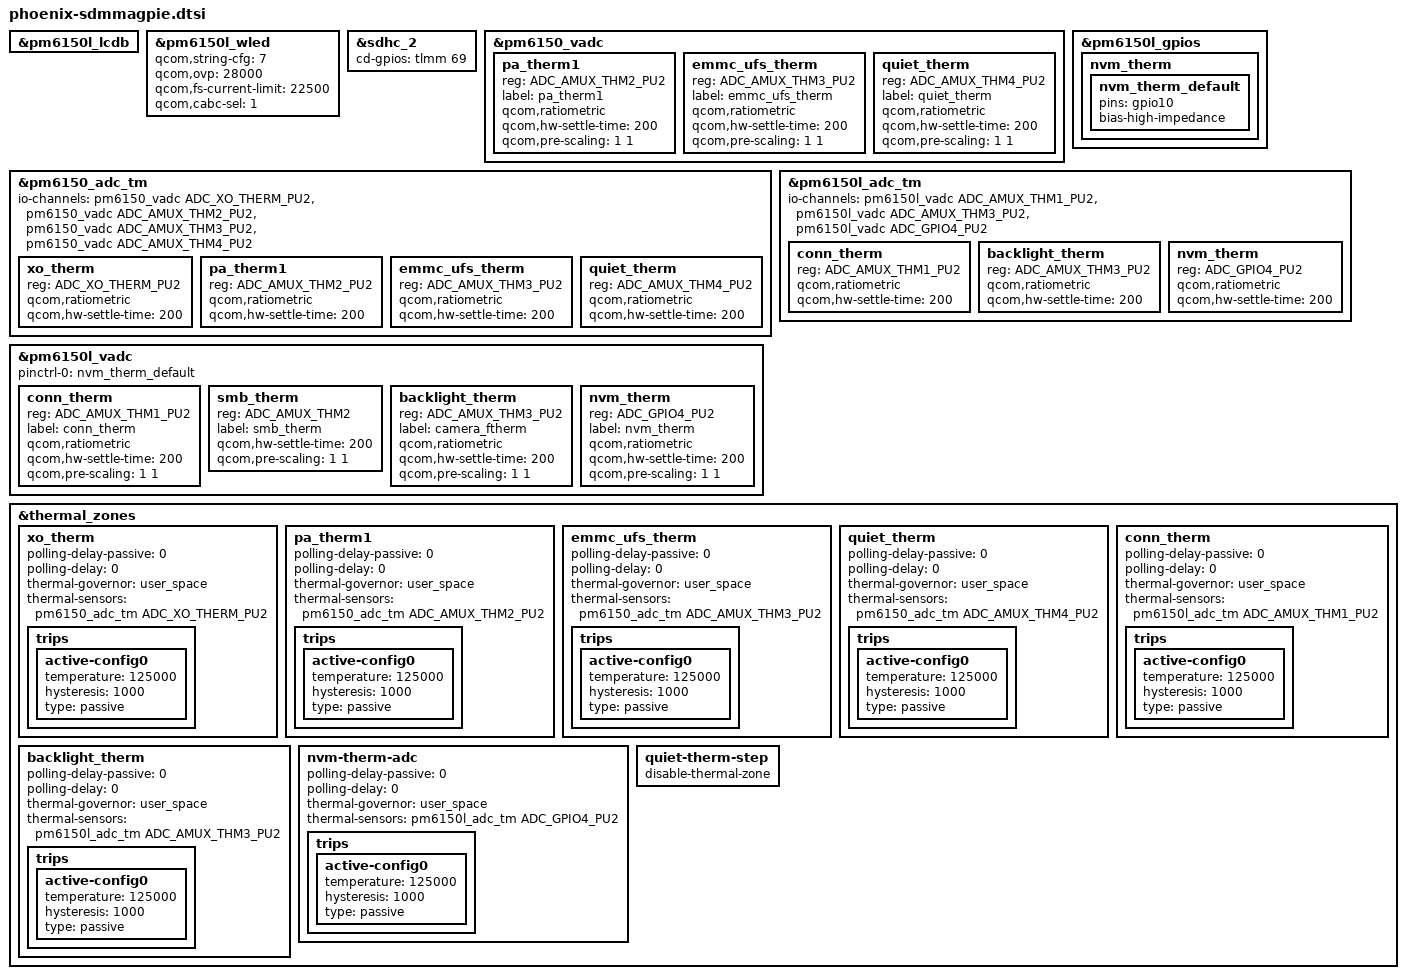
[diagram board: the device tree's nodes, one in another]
/* Copyright (c) 2018-2019, The Linux Foundation. All rights reserved.
 * Copyright (C) 2020 The LineageOS Project
 *
 * This program is free software; you can redistribute it and/or modify
 * it under the terms of the GNU General Public License version 2 and
 * only version 2 as published by the Free Software Foundation.
 *
 * This program is distributed in the hope that it will be useful,
 * but WITHOUT ANY WARRANTY; without even the implied warranty of
 * MERCHANTABILITY or FITNESS FOR A PARTICULAR PURPOSE.  See the
 * GNU General Public License for more details.
 */

#include "../common/xiaomi-sdmmagpie-common.dtsi"

#include "phoenix-audio-overlay.dtsi"
#include "phoenix-nfc-overlay.dtsi"
#include "phoenix-sdmmagpie-battery.dtsi"
#include "phoenix-sdmmagpie-camera-sensor.dtsi"
#include "phoenix-sdmmagpie-display.dtsi"
#include "phoenix-sdmmagpie-fingerprint.dtsi"
#include "phoenix-sdmmagpie-leds.dtsi"
#include "phoenix-sdmmagpie-pinctrl.dtsi"
#include "phoenix-sdmmagpie-touchscreen.dtsi"
#include "phoenix-sdmmagpie-usb.dtsi"

&pm6150l_lcdb {
    status = "okay";
};

&pm6150l_wled {
    status = "okay";
    qcom,string-cfg = <7>;
    qcom,ovp = <28000>;
    qcom,fs-current-limit = <22500>;
    qcom,cabc-sel = <1>;
};

&sdhc_2 {
    cd-gpios = <&tlmm 69 GPIO_ACTIVE_HIGH>;
    status = "ok";
};

&pm6150_vadc {
    pa_therm1 {
        reg = <ADC_AMUX_THM2_PU2>;
        label = "pa_therm1";
        qcom,ratiometric;
        qcom,hw-settle-time = <200>;
        qcom,pre-scaling = <1 1>;
    };

    emmc_ufs_therm {
        reg = <ADC_AMUX_THM3_PU2>;
        label = "emmc_ufs_therm";
        qcom,ratiometric;
        qcom,hw-settle-time = <200>;
        qcom,pre-scaling = <1 1>;
    };

    quiet_therm {
        reg = <ADC_AMUX_THM4_PU2>;
        label = "quiet_therm";
        qcom,ratiometric;
        qcom,hw-settle-time = <200>;
        qcom,pre-scaling = <1 1>;
    };
};

&pm6150_adc_tm {
    io-channels = <&pm6150_vadc ADC_XO_THERM_PU2>,
            <&pm6150_vadc ADC_AMUX_THM2_PU2>,
            <&pm6150_vadc ADC_AMUX_THM3_PU2>,
            <&pm6150_vadc ADC_AMUX_THM4_PU2>;

    /* Channel nodes */
    xo_therm {
        reg = <ADC_XO_THERM_PU2>;
        qcom,ratiometric;
        qcom,hw-settle-time = <200>;
    };

    pa_therm1 {
        reg = <ADC_AMUX_THM2_PU2>;
        qcom,ratiometric;
        qcom,hw-settle-time = <200>;
    };

    emmc_ufs_therm {
        reg = <ADC_AMUX_THM3_PU2>;
        qcom,ratiometric;
        qcom,hw-settle-time = <200>;
    };

    quiet_therm {
        reg = <ADC_AMUX_THM4_PU2>;
        qcom,ratiometric;
        qcom,hw-settle-time = <200>;
    };
};

&pm6150l_vadc {
    pinctrl-names = "default";
    pinctrl-0 = <&nvm_therm_default>;

    conn_therm {
        reg = <ADC_AMUX_THM1_PU2>;
        label = "conn_therm";
        qcom,ratiometric;
        qcom,hw-settle-time = <200>;
        qcom,pre-scaling = <1 1>;
    };

    smb_therm {
        reg = <ADC_AMUX_THM2>;
        label = "smb_therm";
        qcom,hw-settle-time = <200>;
        qcom,pre-scaling = <1 1>;
    };

    backlight_therm {
        reg = <ADC_AMUX_THM3_PU2>;
        label = "camera_ftherm";
        qcom,ratiometric;
        qcom,hw-settle-time = <200>;
        qcom,pre-scaling = <1 1>;
    };

    nvm_therm {
        reg = <ADC_GPIO4_PU2>;
        label = "nvm_therm";
        qcom,ratiometric;
        qcom,hw-settle-time = <200>;
        qcom,pre-scaling = <1 1>;
    };
};

&pm6150l_gpios {
    nvm_therm {
        nvm_therm_default: nvm_therm_default {
            pins = "gpio10";
            bias-high-impedance;
        };
    };
};

&pm6150l_adc_tm {
    io-channels = <&pm6150l_vadc ADC_AMUX_THM1_PU2>,
            <&pm6150l_vadc ADC_AMUX_THM3_PU2>,
            <&pm6150l_vadc ADC_GPIO4_PU2>;

    /* Channel nodes */
    conn_therm {
        reg = <ADC_AMUX_THM1_PU2>;
        qcom,ratiometric;
        qcom,hw-settle-time = <200>;
    };

    backlight_therm {
        reg = <ADC_AMUX_THM3_PU2>;
        qcom,ratiometric;
        qcom,hw-settle-time = <200>;
    };

    nvm_therm {
        reg = <ADC_GPIO4_PU2>;
        qcom,ratiometric;
        qcom,hw-settle-time = <200>;
    };
};

&thermal_zones {
    xo_therm {
        polling-delay-passive = <0>;
        polling-delay = <0>;
        thermal-governor = "user_space";
        thermal-sensors = <&pm6150_adc_tm ADC_XO_THERM_PU2>;
        trips {
            active-config0 {
                temperature = <125000>;
                hysteresis = <1000>;
                type = "passive";
            };
        };
    };

    pa_therm1 {
        polling-delay-passive = <0>;
        polling-delay = <0>;
        thermal-governor = "user_space";
        thermal-sensors = <&pm6150_adc_tm ADC_AMUX_THM2_PU2>;
        trips {
            active-config0 {
                temperature = <125000>;
                hysteresis = <1000>;
                type = "passive";
            };
        };
    };

    emmc_ufs_therm {
        polling-delay-passive = <0>;
        polling-delay = <0>;
        thermal-governor = "user_space";
        thermal-sensors = <&pm6150_adc_tm ADC_AMUX_THM3_PU2>;
        trips {
            active-config0 {
                temperature = <125000>;
                hysteresis = <1000>;
                type = "passive";
            };
        };
    };

    quiet_therm {
        polling-delay-passive = <0>;
        polling-delay = <0>;
        thermal-governor = "user_space";
        thermal-sensors = <&pm6150_adc_tm ADC_AMUX_THM4_PU2>;
        trips {
            active-config0 {
                temperature = <125000>;
                hysteresis = <1000>;
                type = "passive";
            };
        };
    };

    conn_therm {
        polling-delay-passive = <0>;
        polling-delay = <0>;
        thermal-governor = "user_space";
        thermal-sensors = <&pm6150l_adc_tm ADC_AMUX_THM1_PU2>;
        trips {
            active-config0 {
                temperature = <125000>;
                hysteresis = <1000>;
                type = "passive";
            };
        };
    };

    backlight_therm {
        polling-delay-passive = <0>;
        polling-delay = <0>;
        thermal-governor = "user_space";
        thermal-sensors = <&pm6150l_adc_tm ADC_AMUX_THM3_PU2>;
        trips {
            active-config0 {
                temperature = <125000>;
                hysteresis = <1000>;
                type = "passive";
            };
        };
    };

    nvm-therm-adc {
        polling-delay-passive = <0>;
        polling-delay = <0>;
        thermal-governor = "user_space";
        thermal-sensors = <&pm6150l_adc_tm ADC_GPIO4_PU2>;
        trips {
            active-config0 {
                temperature = <125000>;
                hysteresis = <1000>;
                type = "passive";
            };
        };
    };

    quiet-therm-step {
        disable-thermal-zone;
    };
};
